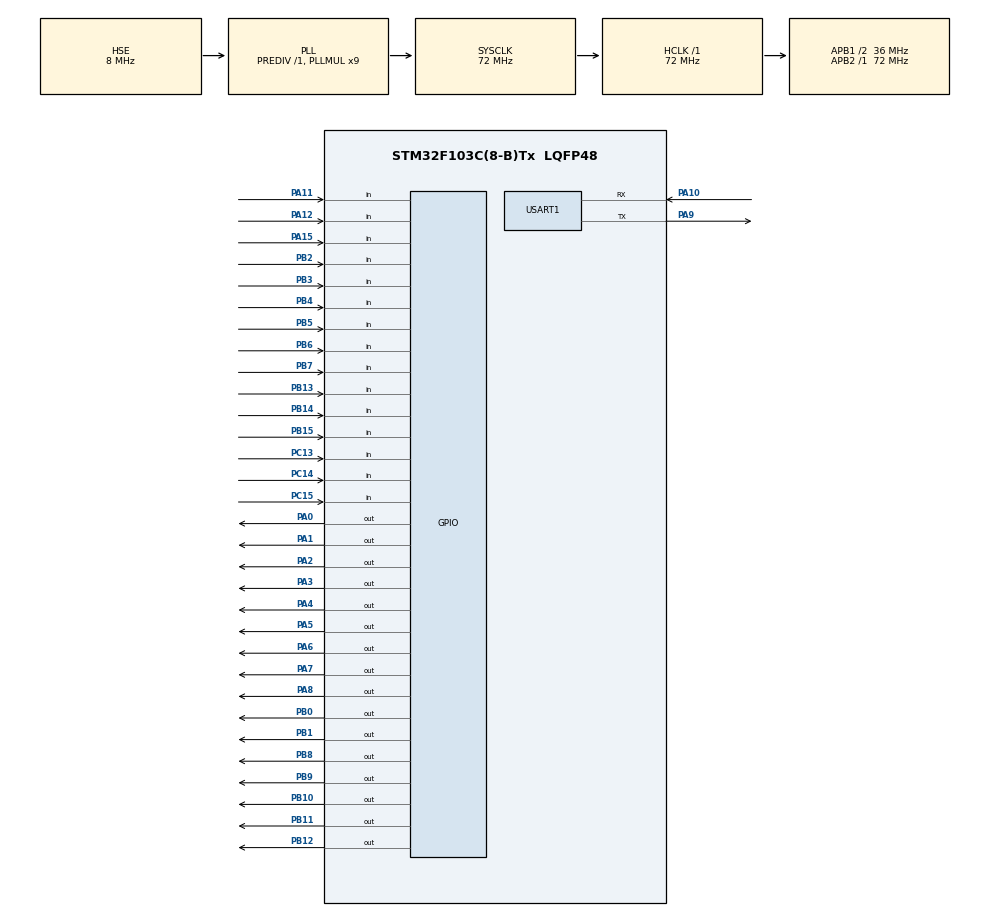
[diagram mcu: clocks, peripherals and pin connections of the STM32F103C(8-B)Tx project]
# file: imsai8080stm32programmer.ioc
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Dma.Request0=USART1_RX
Dma.USART1_RX.0.Direction=DMA_PERIPH_TO_MEMORY
Dma.USART1_RX.0.Instance=DMA1_Channel5
Dma.USART1_RX.0.MemDataAlignment=DMA_MDATAALIGN_BYTE
Dma.USART1_RX.0.MemInc=DMA_MINC_ENABLE
Dma.USART1_RX.0.Mode=DMA_CIRCULAR
Dma.USART1_RX.0.PeriphDataAlignment=DMA_PDATAALIGN_BYTE
Dma.USART1_RX.0.PeriphInc=DMA_PINC_DISABLE
Dma.USART1_RX.0.Priority=DMA_PRIORITY_LOW
FREERTOS.Tasks01=defaultTask,0,128,StartDefaultTask,Default,NULL
Mcu.Family=STM32F1
Mcu.Name=STM32F103C(8-B)Tx
Mcu.Package=LQFP48
NVIC.DMA1_Channel5_IRQn=true\:5\:0\:false\:false\:true\:true\:false
NVIC.PriorityGroup=NVIC_PRIORITYGROUP_4
NVIC.TIM1_UP_IRQn=true\:0\:0\:false\:false\:true\:false\:false
NVIC.TimeBase=TIM1_UP_IRQn
NVIC.TimeBaseIP=TIM1
NVIC.USART1_IRQn=true\:5\:0\:false\:false\:true\:true\:true
PA0-WKUP.Signal=GPIO_Output
PA1.Signal=GPIO_Output
PA10.Mode=Asynchronous
PA10.Signal=USART1_RX
PA11.Signal=GPIO_Input
PA12.Signal=GPIO_Input
PA13.Mode=Serial_Wire
PA13.Signal=SYS_JTMS-SWDIO
PA14.Mode=Serial_Wire
PA14.Signal=SYS_JTCK-SWCLK
PA15.Signal=GPIO_Input
PA2.Signal=GPIO_Output
PA3.Signal=GPIO_Output
PA4.PinState=GPIO_PIN_SET
PA4.Signal=GPIO_Output
PA5.Signal=GPIO_Output
PA6.Signal=GPIO_Output
PA7.Signal=GPIO_Output
PA8.PinState=GPIO_PIN_SET
PA8.Signal=GPIO_Output
PA9.Mode=Asynchronous
PA9.Signal=USART1_TX
PB0.Signal=GPIO_Output
PB1.Signal=GPIO_Output
PB10.GPIO_ModeDefaultOutputPP=GPIO_MODE_OUTPUT_OD
PB10.PinState=GPIO_PIN_SET
PB10.Signal=GPIO_Output
PB11.GPIO_ModeDefaultOutputPP=GPIO_MODE_OUTPUT_OD
PB11.PinState=GPIO_PIN_SET
PB11.Signal=GPIO_Output
PB12.GPIO_ModeDefaultOutputPP=GPIO_MODE_OUTPUT_OD
PB12.PinState=GPIO_PIN_SET
PB12.Signal=GPIO_Output
PB13.Signal=GPIO_Input
PB14.Signal=GPIO_Input
PB15.Signal=GPIO_Input
PB2.Signal=GPIO_Input
PB3.Signal=GPIO_Input
PB4.Signal=GPIO_Input
PB5.Signal=GPIO_Input
PB6.Signal=GPIO_Input
PB7.Signal=GPIO_Input
PB8.GPIO_ModeDefaultOutputPP=GPIO_MODE_OUTPUT_OD
PB8.PinState=GPIO_PIN_SET
PB8.Signal=GPIO_Output
PB9.GPIO_ModeDefaultOutputPP=GPIO_MODE_OUTPUT_OD
PB9.PinState=GPIO_PIN_SET
PB9.Signal=GPIO_Output
PC13-TAMPER-RTC.Signal=GPIO_Input
PC14-OSC32_IN.Signal=GPIO_Input
PC15-OSC32_OUT.Signal=GPIO_Input
PD0-OSC_IN.Mode=HSE-External-Oscillator
PD0-OSC_IN.Signal=RCC_OSC_IN
PD1-OSC_OUT.Mode=HSE-External-Oscillator
PD1-OSC_OUT.Signal=RCC_OSC_OUT
ProjectManager.HeapSize=0x200
ProjectManager.StackSize=0x400
ProjectManager.TargetToolchain=SW4STM32
RCC.AHBFreq_Value=72000000
RCC.APB1CLKDivider=RCC_HCLK_DIV2
RCC.APB1Freq_Value=36000000
RCC.APB1TimFreq_Value=72000000
RCC.APB2Freq_Value=72000000
RCC.APB2TimFreq_Value=72000000
RCC.HCLKFreq_Value=72000000
RCC.PLLMUL=RCC_PLL_MUL9
RCC.PLLSourceVirtual=RCC_PLLSOURCE_HSE
RCC.SYSCLKFreq_VALUE=72000000
RCC.SYSCLKSource=RCC_SYSCLKSOURCE_PLLCLK
RCC.USBFreq_Value=72000000
USART1.VirtualMode=VM_ASYNC
VP_FREERTOS_VS_ENABLE.Mode=Enabled
VP_SYS_VS_tim1.Mode=TIM1
board=custom

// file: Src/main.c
/* USER CODE BEGIN Header */
/**
  ******************************************************************************
  * @file           : main.c
  * @brief          : Main program body
  ******************************************************************************
  ** This notice applies to any and all portions of this file
  * that are not between comment pairs USER CODE BEGIN and
  * USER CODE END. Other portions of this file, whether
  * inserted by the user or by software development tools
  * are owned by their respective copyright owners.
  *
  * COPYRIGHT(c) 2019 STMicroelectronics
  *
  * Redistribution and use in source and binary forms, with or without modification,
  * are permitted provided that the following conditions are met:
  *   1. Redistributions of source code must retain the above copyright notice,
  *      this list of conditions and the following disclaimer.
  *   2. Redistributions in binary form must reproduce the above copyright notice,
  *      this list of conditions and the following disclaimer in the documentation
  *      and/or other materials provided with the distribution.
  *   3. Neither the name of STMicroelectronics nor the names of its contributors
  *      may be used to endorse or promote products derived from this software
  *      without specific prior written permission.
  *
  * THIS SOFTWARE IS PROVIDED BY THE COPYRIGHT HOLDERS AND CONTRIBUTORS "AS IS"
  * AND ANY EXPRESS OR IMPLIED WARRANTIES, INCLUDING, BUT NOT LIMITED TO, THE
  * IMPLIED WARRANTIES OF MERCHANTABILITY AND FITNESS FOR A PARTICULAR PURPOSE ARE
  * DISCLAIMED. IN NO EVENT SHALL THE COPYRIGHT HOLDER OR CONTRIBUTORS BE LIABLE
  * FOR ANY DIRECT, INDIRECT, INCIDENTAL, SPECIAL, EXEMPLARY, OR CONSEQUENTIAL
  * DAMAGES (INCLUDING, BUT NOT LIMITED TO, PROCUREMENT OF SUBSTITUTE GOODS OR
  * SERVICES; LOSS OF USE, DATA, OR PROFITS; OR BUSINESS INTERRUPTION) HOWEVER
  * CAUSED AND ON ANY THEORY OF LIABILITY, WHETHER IN CONTRACT, STRICT LIABILITY,
  * OR TORT (INCLUDING NEGLIGENCE OR OTHERWISE) ARISING IN ANY WAY OUT OF THE USE
  * OF THIS SOFTWARE, EVEN IF ADVISED OF THE POSSIBILITY OF SUCH DAMAGE.
  *
  ******************************************************************************
  */
/* USER CODE END Header */

#include "main.h"
#include "cmsis_os.h"

/* USER CODE BEGIN Includes */

#include "cpp_main.h"
#include "cpp_callbacks.h"

/* USER CODE END Includes */

UART_HandleTypeDef huart1;
DMA_HandleTypeDef hdma_usart1_rx;

osThreadId defaultTaskHandle;

void SystemClock_Config(void);
static void MX_GPIO_Init(void);
static void MX_DMA_Init(void);
static void MX_USART1_UART_Init(void);
void StartDefaultTask(void const * argument);

int main(void)
{

  /* MCU Configuration--------------------------------------------------------*/

  /* Reset of all peripherals, Initializes the Flash interface and the Systick. */
  HAL_Init();

  /* Configure the system clock */
  SystemClock_Config();

  /* Initialize all configured peripherals */
  MX_GPIO_Init();
  MX_DMA_Init();
  MX_USART1_UART_Init();
  /* USER CODE BEGIN 2 */

  cpp_init();

  /* USER CODE END 2 */

  /* Create the thread(s) */
  /* definition and creation of defaultTask */
  osThreadDef(defaultTask, StartDefaultTask, osPriorityNormal, 0, 128);
  defaultTaskHandle = osThreadCreate(osThread(defaultTask), NULL);

  /* Start scheduler */
  osKernelStart();

  /* We should never get here as control is now taken by the scheduler */

  /* Infinite loop */
  /* USER CODE BEGIN WHILE */
#pragma clang diagnostic push
#pragma clang diagnostic ignored "-Wmissing-noreturn"
  while (1)
  {

    /* USER CODE END WHILE */

    /* USER CODE BEGIN 3 */
  }
#pragma clang diagnostic pop
  /* USER CODE END 3 */
}

void SystemClock_Config(void)
{
  RCC_OscInitTypeDef RCC_OscInitStruct = {0};
  RCC_ClkInitTypeDef RCC_ClkInitStruct = {0};

  /**Initializes the CPU, AHB and APB busses clocks
  */
  RCC_OscInitStruct.OscillatorType = RCC_OSCILLATORTYPE_HSE;
  RCC_OscInitStruct.HSEState = RCC_HSE_ON;
  RCC_OscInitStruct.HSEPredivValue = RCC_HSE_PREDIV_DIV1;
  RCC_OscInitStruct.HSIState = RCC_HSI_ON;
  RCC_OscInitStruct.PLL.PLLState = RCC_PLL_ON;
  RCC_OscInitStruct.PLL.PLLSource = RCC_PLLSOURCE_HSE;
  RCC_OscInitStruct.PLL.PLLMUL = RCC_PLL_MUL9;
  if (HAL_RCC_OscConfig(&RCC_OscInitStruct) != HAL_OK)
  {
    Error_Handler();
  }
  /**Initializes the CPU, AHB and APB busses clocks
  */
  RCC_ClkInitStruct.ClockType = RCC_CLOCKTYPE_HCLK|RCC_CLOCKTYPE_SYSCLK
                              |RCC_CLOCKTYPE_PCLK1|RCC_CLOCKTYPE_PCLK2;
  RCC_ClkInitStruct.SYSCLKSource = RCC_SYSCLKSOURCE_PLLCLK;
  RCC_ClkInitStruct.AHBCLKDivider = RCC_SYSCLK_DIV1;
  RCC_ClkInitStruct.APB1CLKDivider = RCC_HCLK_DIV2;
  RCC_ClkInitStruct.APB2CLKDivider = RCC_HCLK_DIV1;

  if (HAL_RCC_ClockConfig(&RCC_ClkInitStruct, FLASH_LATENCY_2) != HAL_OK)
  {
    Error_Handler();
  }
}

static void MX_USART1_UART_Init(void)
{

  huart1.Instance = USART1;
  huart1.Init.BaudRate = 115200;
  huart1.Init.WordLength = UART_WORDLENGTH_8B;
  huart1.Init.StopBits = UART_STOPBITS_1;
  huart1.Init.Parity = UART_PARITY_NONE;
  huart1.Init.Mode = UART_MODE_TX_RX;
  huart1.Init.HwFlowCtl = UART_HWCONTROL_NONE;
  huart1.Init.OverSampling = UART_OVERSAMPLING_16;
  if (HAL_UART_Init(&huart1) != HAL_OK)
  {
    Error_Handler();
  }

}

static void MX_DMA_Init(void)
{
  /* DMA controller clock enable */
  __HAL_RCC_DMA1_CLK_ENABLE();

  /* DMA interrupt init */
  /* DMA1_Channel5_IRQn interrupt configuration */
  HAL_NVIC_SetPriority(DMA1_Channel5_IRQn, 5, 0);
  HAL_NVIC_EnableIRQ(DMA1_Channel5_IRQn);

}

static void MX_GPIO_Init(void)
{
  GPIO_InitTypeDef GPIO_InitStruct = {0};

  /* GPIO Ports Clock Enable */
  __HAL_RCC_GPIOC_CLK_ENABLE();
  __HAL_RCC_GPIOD_CLK_ENABLE();
  __HAL_RCC_GPIOA_CLK_ENABLE();
  __HAL_RCC_GPIOB_CLK_ENABLE();

  /*Configure GPIO pin Output Level */
  HAL_GPIO_WritePin(GPIOA, GPIO_PIN_0|GPIO_PIN_1|GPIO_PIN_2|GPIO_PIN_3
                          |GPIO_PIN_5|GPIO_PIN_6|GPIO_PIN_7, GPIO_PIN_RESET);

  /*Configure GPIO pin Output Level */
  HAL_GPIO_WritePin(GPIOA, GPIO_PIN_4|GPIO_PIN_8, GPIO_PIN_SET);

  /*Configure GPIO pin Output Level */
  HAL_GPIO_WritePin(GPIOB, GPIO_PIN_0|GPIO_PIN_1, GPIO_PIN_RESET);

  /*Configure GPIO pin Output Level */
  HAL_GPIO_WritePin(GPIOB, GPIO_PIN_10|GPIO_PIN_11|GPIO_PIN_12|GPIO_PIN_8
                          |GPIO_PIN_9, GPIO_PIN_SET);

  /*Configure GPIO pins : PC13 PC14 PC15 */
  GPIO_InitStruct.Pin = GPIO_PIN_13|GPIO_PIN_14|GPIO_PIN_15;
  GPIO_InitStruct.Mode = GPIO_MODE_INPUT;
  GPIO_InitStruct.Pull = GPIO_NOPULL;
  HAL_GPIO_Init(GPIOC, &GPIO_InitStruct);

  /*Configure GPIO pins : PA0 PA1 PA2 PA3
                           PA4 PA5 PA6 PA7
                           PA8 */
  GPIO_InitStruct.Pin = GPIO_PIN_0|GPIO_PIN_1|GPIO_PIN_2|GPIO_PIN_3
                          |GPIO_PIN_4|GPIO_PIN_5|GPIO_PIN_6|GPIO_PIN_7
                          |GPIO_PIN_8;
  GPIO_InitStruct.Mode = GPIO_MODE_OUTPUT_PP;
  GPIO_InitStruct.Pull = GPIO_NOPULL;
  GPIO_InitStruct.Speed = GPIO_SPEED_FREQ_LOW;
  HAL_GPIO_Init(GPIOA, &GPIO_InitStruct);

  /*Configure GPIO pins : PB0 PB1 */
  GPIO_InitStruct.Pin = GPIO_PIN_0|GPIO_PIN_1;
  GPIO_InitStruct.Mode = GPIO_MODE_OUTPUT_PP;
  GPIO_InitStruct.Pull = GPIO_NOPULL;
  GPIO_InitStruct.Speed = GPIO_SPEED_FREQ_LOW;
  HAL_GPIO_Init(GPIOB, &GPIO_InitStruct);

  /*Configure GPIO pins : PB2 PB13 PB14 PB15
                           PB3 PB4 PB5 PB6
                           PB7 */
  GPIO_InitStruct.Pin = GPIO_PIN_2|GPIO_PIN_13|GPIO_PIN_14|GPIO_PIN_15
                          |GPIO_PIN_3|GPIO_PIN_4|GPIO_PIN_5|GPIO_PIN_6
                          |GPIO_PIN_7;
  GPIO_InitStruct.Mode = GPIO_MODE_INPUT;
  GPIO_InitStruct.Pull = GPIO_NOPULL;
  HAL_GPIO_Init(GPIOB, &GPIO_InitStruct);

  /*Configure GPIO pins : PB10 PB11 PB12 PB8
                           PB9 */
  GPIO_InitStruct.Pin = GPIO_PIN_10|GPIO_PIN_11|GPIO_PIN_12|GPIO_PIN_8
                          |GPIO_PIN_9;
  GPIO_InitStruct.Mode = GPIO_MODE_OUTPUT_OD;
  GPIO_InitStruct.Pull = GPIO_NOPULL;
  GPIO_InitStruct.Speed = GPIO_SPEED_FREQ_LOW;
  HAL_GPIO_Init(GPIOB, &GPIO_InitStruct);

  /*Configure GPIO pins : PA11 PA12 PA15 */
  GPIO_InitStruct.Pin = GPIO_PIN_11|GPIO_PIN_12|GPIO_PIN_15;
  GPIO_InitStruct.Mode = GPIO_MODE_INPUT;
  GPIO_InitStruct.Pull = GPIO_NOPULL;
  HAL_GPIO_Init(GPIOA, &GPIO_InitStruct);

}

void StartDefaultTask(void const * argument)
{

  /* USER CODE BEGIN 5 */
    cpp_main();
  /* USER CODE END 5 */
}

void HAL_TIM_PeriodElapsedCallback(TIM_HandleTypeDef *htim)
{
  if (htim->Instance == TIM1) {
    HAL_IncTick();
  }
}

void Error_Handler(void)
{
}

/************************ (C) COPYRIGHT STMicroelectronics *****END OF FILE****/
